# EOS-S3 register map
File version: 0.1
CPU: CM4 r0p1, selectable endian, MPU, FPU, 3 interrupt priority bits
Registers are 32-bit, read-write, reset 0x0 unless marked. A register's access mark holds for its fields unless they carry their own. Offsets are from the block's base; [hi:lo] are bit positions.

## SDMA — System Direct Access Memory
Base 0x4000C000
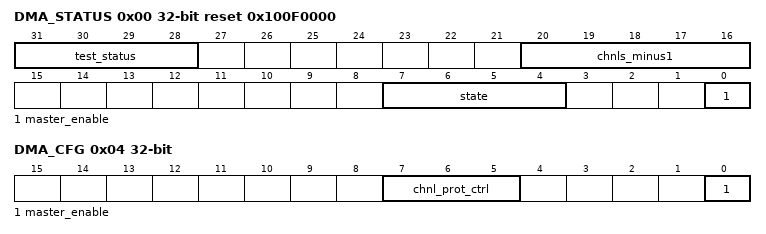
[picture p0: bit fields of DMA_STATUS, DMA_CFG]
0x00 DMA_STATUS ro reset 0x100F0000
  [31:28] test_status — To reduce the gate count you can configure the controller to exclude the integration Test logic. If value = 1, the integration Test logic is included. If 0, Test logic is not included. Any other value is undefined
  [20:16] chnls_minus1 — Number of available DMA channels (value in register + 1)
  [7:4] state — Current state of the control state machine.
    0=idle state; 1=read_ch_cntrl_data (reading channel controller data.); 2=read_src_data_end_ptr (reading source data end pointer); 3=read_dest_data_end_ptr (reading destination data end pointer); 4=read_src_data (reading source data); 5=write_dest_data (writing destination data); 6=wait_dma_req_clear (waiting for DMA request to clear); 7=write_ch_ctrl_data (writing channel controller data); 8=stalled state; 9=done state; 10=periph_scatter_gather_trans (peripheral scatter-gather transition)
  [0] master_enable — Set if controller is enabled
0x04 DMA_CFG — DMA configuration register
  [7:5] chnl_prot_ctrl wo — Sets the AHB-Lite protection by controlling the HPROT[3:1] signal levels as follows: . Bit [7] Controls HPROT[3] to indicate if a cacheable access is occurring. . Bit [6] Controls HPROT[2] to indicate if a bufferable access is occurring. . Bit [5] Controls HPROT[1] to indicate if a privileged access is occurring. . Note . When bit [n] = 1 then the corresponding HPROT is HIGH. . When bit [n] = 0 then the corresponding HPROT is LOW.
  [0] master_enable wo — Set to enable the controller
0x08 CTRL_BASE_PTR — Control the pointer to the base address of the primary data structure
  [31:9] ctrl_base_ptr — Pointer to the base address of the primary data structure
0x0C ALT_CTRL_BASE_PTR reset 0x100 — Base address of the alternate data structure.
  [31:0] alt_ctrl_base_ptr ro — Base address of the alternate data structure
0x10 DMA_WAITONREQ_STATUS — Channel wait on request status
  [15:0] dma_waitonreq_status ro — Channel wait on request status. . Read as: . Bit [C] = 0 dma_waitonreq[C] is LOW. . Bit [C] = 1 dma_waitonreq[C] is HIGH.
0x14 CHNL_SW_REQ — Registers to generate a software DMA request in one of the 16 DMA channels
  [15:0] chnl_sw_request wo — Set the appropriate bit to generate a software DMA request on the corresponding DMA channel. Write as: . Bit [C] = 0 Does not create a DMA request for channel C. . Bit [C] = 1 Creates a DMA request for channel C. . Writing to a bit where a DMA channel is not implemented does not create a DMA request for that channel.
0x18 CHNL_USE_BURST_SET — Returns the useburst status, or disables dma_sreq[Channel] from generating DMA requests
  [15:0] chnl_use_burst_set — Returns the useburst status, or disables dma_sreq[C] from generating DMA requests. Read as: . Bit [C] = 0 DMA channel C responds to requests that it receives on dma_req[C] or dma_sreq[C]. The controller performs 2R, or single, bus transfers. . Bit [C] = 1 DMA channel C does not respond to requests that it receives on dma_sreq[C]. The controller only responds to dma_req[C] requests and performs 2R transfers. . Write as: . Bit [C] = 0 No effect. Use the chnl_useburst_clr Register to set bit [C] to 0. . Bit [C] = 1 Disables dma_sreq[C] from generating DMA requests. The controller performs 2R transfers. . Writing to a bit where a DMA channel is not implemented has no effect.
0x1C CHNL_USEBURST_SET — Set the appropriate bit to enable dma_sreq[Channel] to generate requests.
  [15:0] chnl_useburst_clr wo — Set the appropriate bit to enable dma_sreq[] to generate requests. Write as: . Bit [C] = 0 No effect. Use the chnl_useburst_set Register to disable dma_sreq[] from generating requests. . Bit [C] = 1 Enables dma_sreq[C] to generate DMA requests. . Writing to a bit where a DMA channel is not implemented has no effect
0x20 CHNL_REQ_MASK_SET — Returns the request mask status of dma_req[] and dma_sreq[], or disables the corresponding channel from generating DMA requests.
  [15:0] chnl_req_mask_set — Returns the request mask status of dma_req[C] and dma_sreq[C], or disables the corresponding channel from generating DMA requests. Read as: . Bit [C] = 0 External requests are enabled for channel C. . Bit [C] = 1 External requests are disabled for channel C. . Write as: . Bit [C] = 0 No effect. Use the chnl_req_mask_clr Register to enable DMA requests. Bit [C] = 1 Disables dma_req[C] and dma_sreq[C] from generating DMA requests. Writing to a bit where a DMA channel is not implemented has no effect.
0x24 CHNL_REQ_MASK_CLR — Set the appropriate bit to enable DMA requests for the channel corresponding to dma_req[C] and dma_sreq[C].
  [15:0] chnl_req_mask_cler wo — Set the appropriate bit to enable DMA requests for the channel corresponding to dma_req[C] and dma_sreq[C]. Write as: . Bit [C] = 0 No effect. Use the chnl_req_mask_set Register to disable dma_req[C] and dma_sreq[C] from generating requests. . Bit [C] = 1 Enables dma_req[C] or dma_sreq[C] to generate DMA requests. . Writing to a bit where a DMA channel is not implemented has no effect.
0x28 CHNL_ENABLE_SET — Returns the enable status of the channels, or enables the corresponding channels.
  [15:0] chnl_enable_set — Returns the enable status of the channels, or enables the corresponding channels. Read as: . Bit [C] = 0 Channel C is disabled. . Bit [C] = 1 Channel C is enabled. . Write as: . Bit [C] = 0 No effect. Use the chnl_enable_clr Register to disable a channel. . Bit [C] = 1 Enables channel C. . Writing to a bit where a DMA channel is not implemented has no effect.
0x2C CHNL_ENABLE_CLR — Set the appropriate bit to disable the corresponding DMA channel.
  [15:0] chnl_enable_clr wo — Set the appropriate bit to disable the corresponding DMA channel. Write as: . Bit [C] = 0 No effect. Use the chnl_enable_set Register to enable DMA channels. . Bit [C] = 1 Disables channel C. . Writing to a bit where a DMA channel is not implemented has no effect.
0x30 CHNL_PRI_ALT_SET — Returns the channel control data structure status, or selects the alternate data structure for the corresponding DMA channel.
  [15:0] chnl_pri_alt_set — Returns the channel control data structure status, or selects the alternate data structure for the corresponding DMA channel. Read as: . Bit [C] = 0 DMA channel C is using the primary data structure. . Bit [C] = 1 DMA channel C is using the alternate data structure. . Write as: . Bit [C] = 0 No effect. Use the chnl_pri_alt_clr Register to set bit [C] to 0. . Bit [C] = 1 Selects the alternate data structure for channel C. . Writing to a bit where a DMA channel is not implemented has no effect.
0x34 CHNL_PRI_ALT_CLR — Set the appropriate bit to select the primary data structure for the corresponding DMA channel.
  [15:0] chnl_pri_alt_clr wo — Set the appropriate bit to select the primary data structure for the corresponding DMA channel. Write as: . Bit [C] = 0 No effect. Use the chnl_pri_alt_set Register to select the alternate data structure. . Bit [C] = 1 Selects the primary data structure for channel C. . Writing to a bit where a DMA channel is not implemented has no effect.
0x38 CHNL_PRIORITY_SET — Returns the channel priority mask status, or sets the channel priority to high.
  [15:0] chnl_priority_set wo — Returns the channel priority mask status, or sets the channel priority to high. Read as: . Bit [C] = 0 DMA channel C is using the default priority level. . Bit [C] = 1 DMA channel C is using a high priority level. . Write as: . Bit [C] = 0 No effect. Use the chnl_priority_clr Register to set channel C to the default priority level. . Bit [C] = 1 Channel C uses the high priority level. . Writing to a bit where a DMA channel is not implemented has no effect.
0x3C CHNL_PRIORITY_CLEAR — Set the appropriate bit to select the default priority level for the specified DMA channel.
  [15:0] chnl_priority_clear — Set the appropriate bit to select the default priority level for the specified DMA channel. Write as: . Bit [C] = 0 No effect. Use the chnl_priority_set Register to set channel C to the high priority level. . Bit [C] = 1 Channel C uses the default priority level. . Writing to a bit where a DMA channel is not implemented has no effect.
0x4C ERR_CLR — Returns the status of dma_err, or sets the signal LOW.
  [0] err_clr — Returns the status of dma_err, or sets the signal LOW. Read as: . 0 = dma_err is LOW . 1 = dma_err is HIGH. . Write as: . 0 = No effect, status of dma_err is unchanged. . 1 = Sets dma_err LOW. . For Test purposes, use the err_set register to set dma_err HIGH.
0xFD0 PERIPH_ID_4 reset 0x4 — Peripheral identification 4
  [31:0] periph_id_4 ro
0xFE0 PERIPH_ID_0 reset 0x30 — Peripheral identification 0
  [31:0] periph_id_0 ro
0xFE4 PERIPH_ID_1 reset 0xB2 — Peripheral identification 1
  [31:0] periph_id_1 ro
0xFE8 PERIPH_ID_2 reset 0xB — Peripheral identification 2
  [31:0] periph_id_2 ro
0xFEC PERIPH_ID_3 — Peripheral identification 3
  [31:0] periph_id_3 ro
0xFF0 PCELL_ID_0 reset 0xD — PrimeCell identification 0
  [31:0] pcell_id_0 ro
0xFF0 PCELL_ID_1 reset 0xF0 — PrimeCell identification 1
  [31:0] pcell_id_1 ro
0xFF0 PCELL_ID_2 reset 0x5 — PrimeCell identification 2
  [31:0] pcell_id_2 ro
0xFF0 PCELL_ID_3 reset 0xB1 — PrimeCell identification 3
  [31:0] pcell_id_3 ro
